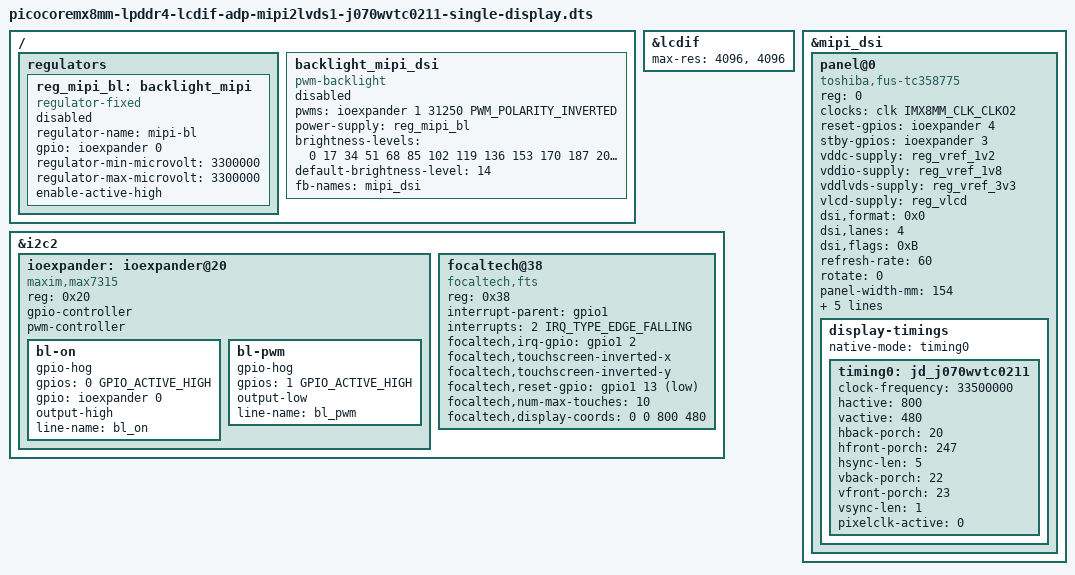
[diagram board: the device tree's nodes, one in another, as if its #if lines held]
/*
 * Copyright (C) 2019 F&S Elektronik Systeme GmbH
 *
 * This program is free software; you can redistribute it and/or modify
 * it under the terms of the GNU General Public License version 2 as
 * published by the Free Software Foundation.
 */

#define CONFIG_PICOCOREMX8MM_MIPI_DSI
#define CONFIG_PICOCOREMX8MM_INVERTED_XY
#define CONFIG_MIPI2LVDS1_BOARD_REVISION 120
#define CONFIG_MIPI2LVDS1_MAXIM_MAX7315
//#define CONFIG_MIPI2LVDS1_TI_TCA9534

#ifdef CONFIG_MIPI2LVDS1_MAXIM_MAX7315
#undef CONFIG_MIPI2LVDS1_TI_TCA9534
#endif

#if CONFIG_MIPI2LVDS1_BOARD_REVISION != 120
#undef CONFIG_MIPI2LVDS1_MAXIM_MAX7315
#undef CONFIG_MIPI2LVDS1_TI_TCA9534
#endif


#include "picocoremx8mm-lpddr4.dts"

&lcdif {
	status = "okay";
	/* important to overwrite max-res otherwise DRM lcdif will fail
	 * to find a suitable connector
	 */
	max-res = <4096>, <4096>;
};

#if CONFIG_MIPI2LVDS1_BOARD_REVISION >= 100
&mipi_dsi {
	status = "okay";
	panel@0{
		status = "okay";
		compatible = "toshiba,fus-tc358775";
		reg = <0>;
		//pinctrl-names = "default";
		//pinctrl-0 = <&pinctrl_mipi_dsi_lvds_en>;
		clocks = <&clk IMX8MM_CLK_CLKO2>;
#if CONFIG_MIPI2LVDS1_BOARD_REVISION == 120
		reset-gpios = <&ioexpander 4 GPIO_ACTIVE_HIGH>;
		stby-gpios  = <&ioexpander 3 GPIO_ACTIVE_HIGH>;
#endif
		vddc-supply = <&reg_vref_1v2>;
		vddio-supply = <&reg_vref_1v8>;
		vddlvds-supply = <&reg_vref_3v3>;
		vlcd-supply = <&reg_vlcd>;
		dsi,format = <0x0>; /* MIPI_DSI_FMT_RGB888 */
		dsi,lanes = <4>;
		/* MIPI_DSI_MODE_VIDEO MIPI_DSI_MODE_VIDEO_BURST
		 * MIPI_DSI_MODE_VIDEO_AUTO_VERT
		 */
		dsi,flags = <0xB>;
		refresh-rate = <60>;
                rotate = <0>;
		panel-width-mm = <154>;
		panel-height-mm = <85>;
		reg,address = <
			/* dsi basic parameters in lp mode */
			0x013c 0x0114 0x0164 0x0168
			0x016C 0x0170 0x0134 0x0210
			0x0104 0x0204
			/* Timing and mode settings */
			0x0450 0x0454 0x0458 0x045C
			0x0460 0x0464 0x04A0 0x04A0 0x0504
			/* color mapping settings	*/
			0x0480 0x0484 0x0488 0x048C 0x0490
			0x0494 0x0498
			/* LVDS enable */
			0x049C
		>;
		reg,value = <
			/* dsi basic parameters in lp mode */
			0x10002 0x1 0x0 0x0
			0x00000	0x0 0x1F 0x1F
			0x00001 0x1
			/* Timing and mode settings */
			0x03200120 0x1A0014 0xD20320 0x170001
			0x1501E0 0x1 0x44802D 0x4802D 0x4
			/* color mapping settings	*/
			0x3020100 0x8050704 0xF0E0A09 0x100D0C0B 0x12111716
			0x1B151413 0x61A1918 0x00000031
		>;

		display-timings {
			native-mode = <&timing0>;
			timing0: jd_j070wvtc0211 {
				clock-frequency = <33500000>;
				hactive = <800>;
				vactive = <480>;
				hback-porch = <20>;
				hfront-porch = <247>;
				hsync-len = <5>;
				vback-porch = <22>;
				vfront-porch = <23>;
				vsync-len = <1>;
				pixelclk-active = <0>;
			};
		};
	};
};
#else
&mipi_dsi {
	status = "okay";
	panel@0 {
		reg = <0>;
		compatible = "fs,j070wvtc0211-dsi"; /* one of panel-simple's
		     		          match strings */
		power-supply = <&reg_vlcd>;
		/* MIPI_DSI_MODE_VIDEO MIPI_DSI_MODE_VIDEO_BURST
		 * MIPI_DSI_MODE_VIDEO_AUTO_VERT
		 */
		dsi,flags = <0xB>;
		dsi,format = <0x0>; /* MIPI_DSI_FMT_RGB888 */
		dsi,lanes = <4>;
		bus-flags = <1>;
		refresh-rate = <60>;
                rotate = <0>;
                bus-format = <0x100a>;
		panel-width-mm = <154>;
		panel-height-mm = <85>;
		display-timings {
			native-mode = <&timing0>;
			timing0: jd_j070wvtc0211 {
				clock-frequency = <33300000>;
				hactive = <800>;
				vactive = <480>;
				hback-porch = <10>;
				hfront-porch = <37>;
				hsync-len = <128>;
				vback-porch = <23>;
				vfront-porch = <11>;
				vsync-len = <1>;
				pixelclk-active = <0>;
				de-active = <1>;
				vsync-active = <0>;
				hsync-active = <0>;
			};
		};
	};
};
#endif

&i2c2 {
#if CONFIG_MIPI2LVDS1_BOARD_REVISION == 100
    /* mipi to lvds controller  */
	dsi_lvds_bridge: sn65dsi84@2c {
		reg = <0x2c>;
		status = "okay";
		compatible = "ti,sn65dsi84";
		#gpio-cells = <2>;
		#if 0
		/* <&pinctrl_mipi_dsi_rst>; */
		enable-gpios = <&gpio1 1 GPIO_ACTIVE_LOW>;
		#endif
		sn65dsi84,addresses = <
			0x09 0x0A 0x0B 0x0D
			0x10 0x11 0x12 0x13
			0x18 0x19 0x1A 0x1B
			0x20 0x21 0x22 0x23
			0x24 0x25 0x26 0x27
			0x28 0x29 0x2A 0x2B
			0x2C 0x2D 0x2E 0x2F
			0x30 0x31 0x32 0x33
			0x34 0x35 0x36 0x37
			0x38 0x39 0x3A 0x3B
			0x3C 0x3D 0x3E 0x0D
		>;

		sn65dsi84,values = <
			/* reset and clock registers */
			0x00 0x01 0x10 0x00
			/* DSI registers */
			0x26 0x00 0x14 0x00
			/* LVDS registers */
			0x78 0x00 0x03 0x00
			/* video registers */
			/* cha-al-len-l, cha-al-len-h */
			0x20 0x03 0x00 0x00
			/* cha-v-ds-l, cha-v-ds-h */
			0x00 0x00 0x00 0x00
			/* cha-sdl, cha-sdh*/
			0x21 0x00 0x00 0x00
			/* cha-hs-pwl, cha-hs-pwh */
			0x01 0x00 0x00 0x00
			/* cha-vs-pwl, cha-vs-pwh */
			0x01 0x00 0x00 0x00
			/*cha-hbp, cha-vbp */
			0x2e 0x00 0x00 0x00
			/* cha-hfp, cha-vfp*/
			0x00 0x00 0x00 0x00
			0x00 0x00 0x00 0x01
		>;
	};
#endif

#if CONFIG_MIPI2LVDS1_BOARD_REVISION == 120
	/* LED-driver on adapter board MIPI2MIPI1 */
	ioexpander: ioexpander@20 { /* LED-driver */
#ifdef CONFIG_MIPI2LVDS1_MAXIM_MAX7315
		compatible = "maxim,max7315";
#elif defined CONFIG_MIPI2LVDS1_TI_TCA9534
		compatible = "nxp,pca9534";
#endif
		reg = <0x20>;
		/* interrupt not yet supported */
		//interrupt-parent = <&gpio4>;
		//interrupts = <31 IRQ_TYPE_LEVEL_LOW>;
		//#interrupt-cells = <2>;
		//interrupt-controller;
		gpio-controller;
		#gpio-cells = <2>;
#ifndef CONFIG_MIPI2LVDS1_TI_TCA9534
		pwm-controller;
#endif
		#pwm-cells = <3>;
		//#interrupt-cells = <2>;
		//interrupt-controller;
#ifdef CONFIG_MIPI2LVDS1_TI_TCA9534
		bl-on {
			gpio-hog;
			gpios = <0 GPIO_ACTIVE_HIGH>;
			gpio = <&ioexpander 0 GPIO_ACTIVE_HIGH>;
			output-high;
			line-name = "bl_on";
		};
		bl-pwm {
			gpio-hog;
			gpios = <1 GPIO_ACTIVE_HIGH>;
			output-low;
			line-name = "bl_pwm";
		};
#endif
	};
#endif
	/* touch I2C */
	focaltech@38 {
		compatible = "focaltech,fts";
		reg = <0x38>;
#if (CONFIG_PICOCOREMX8MM_BOARD_REVISION==100)
		interrupt-parent = <&gpio1>;
		interrupts = <2 IRQ_TYPE_EDGE_FALLING>;
		focaltech,irq-gpio = <&gpio1 2 IRQ_TYPE_EDGE_FALLING>;
#else
		interrupt-parent = <&gpio4>;
		interrupts = <31 IRQ_TYPE_EDGE_FALLING>;
		focaltech,irq-gpio = <&gpio4 31 IRQ_TYPE_EDGE_FALLING>;
#endif
#ifdef CONFIG_PICOCOREMX8MM_INVERTED_XY
		focaltech,touchscreen-inverted-x;
		focaltech,touchscreen-inverted-y;
#endif
#if CONFIG_PICOCOREMX8MM_BOARD_REVISION >= 130
		focaltech,reset-gpio = <&gpio1 13 GPIO_ACTIVE_LOW>;
#else
		focaltech,reset-gpio = <&gpio1 0 GPIO_ACTIVE_LOW>;
#endif
		focaltech,num-max-touches = <10>;
		focaltech,display-coords = <0 0 800 480>;
	};
};

/ {
	regulators {
		/* BL_ON on adapter board MIPI2MIPI1 */
		reg_mipi_bl: backlight_mipi {
			compatible = "regulator-fixed";
			regulator-name = "mipi-bl";
#if CONFIG_MIPI2LVDS1_BOARD_REVISION == 120
			gpio = <&ioexpander 0 GPIO_ACTIVE_HIGH>;
#if defined CONFIG_MIPI2LVDS1_TI_TCA9534
		status = "disabled";
#endif
#endif
			regulator-min-microvolt = <3300000>;
			regulator-max-microvolt = <3300000>;
			enable-active-high;
		};
	};

	/* MIPI-DSI backlight PWM on adapter MIPI2LVDS1 */
	backlight_mipi_dsi {
		compatible = "pwm-backlight";
		/* only 32 kHz available */
#if CONFIG_MIPI2LVDS1_BOARD_REVISION == 120
		pwms = <&ioexpander 1 31250 PWM_POLARITY_INVERTED>;
#if defined CONFIG_MIPI2LVDS1_TI_TCA9534
		status = "disabled";
#endif
#endif
		power-supply = <&reg_mipi_bl>;
		/* calculated without sigma so it´s linear */
		brightness-levels = <0 17 34 51 68 85 102 119 136
				     153 170 187 204 221 238 255>;
		default-brightness-level = <14>;
		fb-names = "mipi_dsi";
	};
};
